# LPC11E6x register map
File version: 0.8
CPU: CM0PLUS r0p1, little endian, no MPU, no FPU, 0x2 interrupt priority bits, 0x0 interrupts
Registers are 32-bit, read-write, reset 0x0 unless marked. A register's access mark holds for its fields unless they carry their own. Offsets are from the block's base; [hi:lo] are bit positions; {n}, {i} and the like mark numbered series; 'fields as' and 'values as' point back to an identical list.

## CT32B0 — 32-bit counter/timers CT32B0
Base 0x40014000
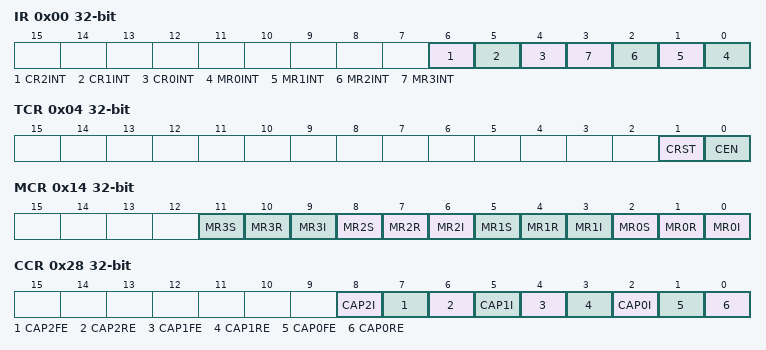
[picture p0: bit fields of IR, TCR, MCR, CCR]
0x00 IR — Interrupt Register. The IR can be written to clear interrupts. The IR can be read to identify which of eight possible interrupt sources are pending.
  [6] CR2INT — Interrupt flag for capture channel 2 event.
  [5] CR1INT — Interrupt flag for capture channel 1 event.
  [4] CR0INT — Interrupt flag for capture channel 0 event.
  [n] MR{n}INT (n=0..3) — Interrupt flag for match channel {n}.
0x04 TCR — Timer Control Register. The TCR is used to control the Timer Counter functions. The Timer Counter can be disabled or reset through the TCR.
  [1] CRST — Counter reset.
    0=NOP (Do nothing.); 1=RESET (The Timer Counter and the Prescale Counter are synchronously reset on the next positive edge of PCLK. The counters remain reset until TCR[1] is returned to zero.)
  [0] CEN — Counter enable.
    0=DISABLED (The counters are disabled.); 1=ENABLED (The Timer Counter and Prescale Counter are enabled for counting.)
0x08 TC — Timer Counter. The 32-bit TC is incremented every PR+1 cycles of PCLK. The TC is controlled through the TCR.
  [31:0] TCVAL — Timer counter value.
0x0C PR — Prescale Register. When the Prescale Counter (below) is equal to this value, the next clock increments the TC and clears the PC.
  [31:0] PCVAL — Prescaler value.
0x10 PC — Prescale Counter. The 32-bit PC is a counter which is incremented to the value stored in PR. When the value in PR is reached, the TC is incremented and the PC is cleared. The PC is observable and controllable through the bus interface.
  [31:0] PC — Prescale counter value.
0x14 MCR — Match Control Register. The MCR is used to control if an interrupt is generated and if the TC is reset when a Match occurs.
  [all] fields
    1=ENABLED; 0=DISABLED
  [3n+2] MR{n}S (n=0..3) — Stop on MR{n}: the TC and PC will be stopped and TCR[0] will be set to 0 if MR{n} matches the TC.
  [3n+1] MR{n}R (n=0..3) — Reset on MR{n}: the TC will be reset if MR{n} matches it.
  [3n] MR{n}I (n=0..3) — Interrupt on MR{n}: an interrupt is generated when MR{n} matches the value in the TC.
{0x18+4i} MR{i} (i=0..3) — Match Register. MR can be enabled through the MCR to reset the TC, stop both the TC and PC, and/or generate an interrupt every time MR0 matches the TC.
  [31:0] MATCH — Timer counter match value.
0x28 CCR — Capture Control Register. The CCR controls which edges of the capture inputs are used to load the Capture Registers and whether or not an interrupt is generated when a capture takes place.
  [all] fields
    1=ENABLED; 0=DISABLED
  [8] CAP2I — Generate interrupt on channel 2 capture event: a CR2 load generates an interrupt.
  [7] CAP2FE — Falling edge of capture channel 2: a sequence of 1 then 0 causes CR2 to be loaded with the contents of TC.
  [6] CAP2RE — Rising edge of capture channel 2: a sequence of 0 then 1 causes CR2 to be loaded with the contents of TC.
  [5] CAP1I — Generate interrupt on channel 1 capture event: a CR1 load generates an interrupt.
  [4] CAP1FE — Falling edge of capture channel 1:: a sequence of 1 then 0 causes CR1 to be loaded with the contents of TC.
  [3] CAP1RE — Rising edge of capture channel 1: a sequence of 0 then 1 causes CR1 to be loaded with the contents of TC.
  [2] CAP0I — Generate interrupt on channel 0 capture event: a CR0 load generates an interrupt.
  [1] CAP0FE — Falling edge of capture channel 0:: a sequence of 1 then 0 causes CR0 to be loaded with the contents of TC.
  [0] CAP0RE — Rising edge of capture channel 0: a sequence of 0 then 1 causes CR0 to be loaded with the contents of TC.
{0x2C+4i} CR{i} ro (i=0..2) — Capture Register. CR is loaded with the value of TC when there is an event on the CAP input.
  [31:0] CAP — Timer counter capture value.
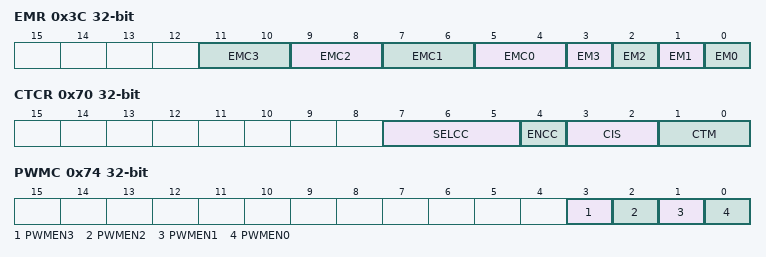
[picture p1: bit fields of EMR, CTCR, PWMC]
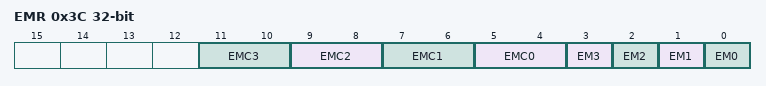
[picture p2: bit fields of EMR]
0x3C EMR — External Match Register. The EMR controls the match function and the external match pins CT32Bn_MAT[3:0].
  [2n+5:2n+4] EMC{n} (n=0..3) — External Match Control {n}. Determines the functionality of External Match {n}.
    0=NOP (Do Nothing.); 1=CLEAR (Clear the corresponding External Match bit/output to 0 (CT32Bi_MAT0 pin is LOW if pinned out).); 2=SET (Set the corresponding External Match bit/output to 1 (CT32Bi_MAT0 pin is HIGH if pinned out).); 3=TOGGLE (Toggle the corresponding External Match bit/output.)
  [3] EM3 — External Match 3. This bit reflects the state of output CT32Bn_MAT3, whether or not this output is connected to its pin. When a match occurs between the TC and MR3, this bit can either toggle, go LOW, go HIGH, or do nothing. Bits EMR[11:10] control the functionality of this output. This bit is driven to the CT32B3_MAT0/CT32B1_MAT3 pins if the match function is selected in the IOCON registers (0 = LOW, 1 = HIGH).
  [2] EM2 — External Match 2. This bit reflects the state of output CT32Bn_MAT2, whether or not this output is connected to its pin. When a match occurs between the TC and MR2, this bit can either toggle, go LOW, go HIGH, or do nothing. Bits EMR[9:8] control the functionality of this output. This bit is driven to the CT32B0_MAT2/CT32B1_MAT2 pins if the match function is selected in the IOCON registers (0 = LOW, 1 = HIGH).
  [1] EM1 — External Match 1. This bit reflects the state of output CT32Bn_MAT1, whether or not this output is connected to its pin. When a match occurs between the TC and MR1, this bit can either toggle, go LOW, go HIGH, or do nothing. Bits EMR[7:6] control the functionality of this output. This bit is driven to the CT32B0_MAT1/CT32B1_MAT1 pins if the match function is selected in the IOCON registers (0 = LOW, 1 = HIGH).
  [0] EM0 — External Match 0. This bit reflects the state of output CT32Bn_MAT0, whether or not this output is connected to its pin. When a match occurs between the TC and MR0, this bit can either toggle, go LOW, go HIGH, or do nothing. Bits EMR[5:4] control the functionality of this output. This bit is driven to the CT32B0_MAT0/CT32B1_MAT0 pins if the match function is selected in the IOCON registers (0 = LOW, 1 = HIGH).
0x70 CTCR — Count Control Register. The CTCR selects between Timer and Counter mode, and in Counter mode selects the signal and edge(s) for counting.
  [7:5] SELCC — Edge select. When bit 4 is 1, these bits select which capture input edge will cause the timer and prescaler to be cleared. These bits have no effect when bit 4 is low. Values 0x2 to 0x3 and 0x6 to 0x7 are reserved.
    0=CAP0RISING (Rising Edge of the signal on capture channel 0 clears the timer (if bit 4 is set).); 1=CAP0FALLING (Falling Edge of the signal on capture channel 0 clears the timer (if bit 4 is set).); 2=CAP1RISING (Rising Edge of the signal on capture channel 1 clears the timer (if bit 4 is set).); 3=CAP1FALLING (Falling Edge of the signal on capture channel 1 clears the timer (if bit 4 is set).); 4=CAP2RISING (Rising Edge of the signal on capture channel 2 clears the timer (if bit 4 is set).); 5=CAP2FALLING (Falling Edge of the signal on capture channel 2 clears the timer (if bit 4 is set).)
  [4] ENCC — Setting this bit to 1 enables clearing of the timer and the prescaler when the capture-edge event specified in bits 7:5 occurs.
  [3:2] CIS — Count Input Select. In counter mode (when bits 1:0 in this register are not 00), these bits select which CAP pin is sampled for clocking. Value 0x3 is reserved.
    0=CAPTURE_CHANNEL_0; 1=CAPTURE_CHANNEL_1; 2=CAPTURE_CHANNEL_2
  [1:0] CTM — Counter/Timer Mode. This field selects which rising PCLK edges can increment the Timer's Prescale Counter (PC), or clear PC and increment Timer Counter (TC). If Counter mode is selected in the CTCR, bits 2:0 in the Capture Control Register (CCR) must be programmed as 000.
    0=TIMER_MODE (Timer Mode. Increments every rising PCLK edge); 1=COUNTER_MODE_RISING (Counter Mode rising edge. TC is incremented on rising edges on the CAP input selected by bits 3:2.); 2=COUNTER_MODE_FALLING (Counter Mode falling edge. TC is incremented on falling edges on the CAP input selected by bits 3:2.); 3=COUNTER_MODE_DUAL_ED (Counter Mode dual edge. TC is incremented on both edges on the CAP input selected by bits 3:2.)
0x74 PWMC — PWM Control Register. The PWMCON enables PWM mode for the external match pins CT32Bn_MAT[3:0].
  [3] PWMEN3 — PWM mode enable for channel3. Note: It is recommended to use match channel 3 to set the PWM cycle.
    0=EM3 (CT32Bn_MAT3 is controlled by EM3.); 1=PWM (PWM mode is enabled for CT132Bn_MAT3.)
  [2] PWMEN2 — PWM mode enable for channel2.
    0=EM2 (CT32Bn_MAT2 is controlled by EM2.); 1=PWM (PWM mode is enabled for CT32Bn_MAT2.)
  [1] PWMEN1 — PWM mode enable for channel1.
    0=EM1 (CT32Bn_MAT01 is controlled by EM1.); 1=PWM (PWM mode is enabled for CT32Bn_MAT1.)
  [0] PWMEN0 — PWM mode enable for channel0.
    0=EM0 (CT32Bn_MAT0 is controlled by EM0.); 1=PWM (PWM mode is enabled for CT32Bn_MAT0.)

## CT32B1 — 32-bit counter/timers CT32B1
Base 0x40018000
Registers as CT32B0; these are added or differ:
0x3C EMR — External Match Register. The EMR controls the match function and the external match pins CT32Bn_MAT[3:0].
  fields as CT32B0.EMR
